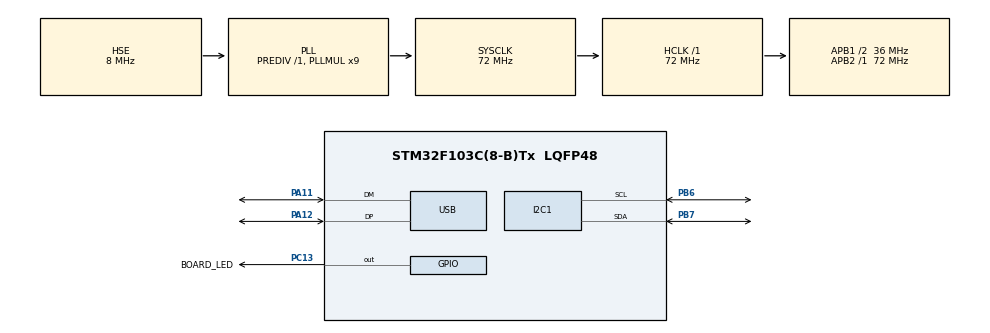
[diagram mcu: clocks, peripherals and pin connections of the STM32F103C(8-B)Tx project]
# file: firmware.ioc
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FREERTOS.Tasks01=imuTask,0,64,imuTaskMain,Default,NULL,Dynamic,NULL,NULL;ledTask,-2,64,ledTaskMain,Default,NULL,Dynamic,NULL,NULL;cdcTask,0,64,cdcTaskMain,Default,NULL,Dynamic,NULL,NULL
FREERTOS.configMINIMAL_STACK_SIZE=64
I2C1.I2C_Mode=I2C_Standard
Mcu.Family=STM32F1
Mcu.Name=STM32F103C(8-B)Tx
Mcu.Package=LQFP48
NVIC.PriorityGroup=NVIC_PRIORITYGROUP_4
NVIC.TIM1_UP_IRQn=true\:0\:0\:false\:false\:true\:false\:false
NVIC.TimeBase=TIM1_UP_IRQn
NVIC.TimeBaseIP=TIM1
NVIC.USB_LP_CAN1_RX0_IRQn=true\:5\:0\:false\:false\:true\:true\:false
PA11.Mode=Device
PA11.Signal=USB_DM
PA12.Mode=Device
PA12.Signal=USB_DP
PA13.Mode=Serial_Wire
PA13.Signal=SYS_JTMS-SWDIO
PA14.Mode=Serial_Wire
PA14.Signal=SYS_JTCK-SWCLK
PB6.Mode=I2C
PB6.Signal=I2C1_SCL
PB7.Mode=I2C
PB7.Signal=I2C1_SDA
PC13-TAMPER-RTC.GPIO_Label=BOARD_LED
PC13-TAMPER-RTC.Signal=GPIO_Output
PD0-OSC_IN.GPIO_Label=XTAL_IN
PD0-OSC_IN.Mode=HSE-External-Oscillator
PD0-OSC_IN.Signal=RCC_OSC_IN
PD1-OSC_OUT.GPIO_Label=XTAL_OUT
PD1-OSC_OUT.Mode=HSE-External-Oscillator
PD1-OSC_OUT.Signal=RCC_OSC_OUT
ProjectManager.HeapSize=0x200
ProjectManager.StackSize=0x400
ProjectManager.TargetToolchain=TrueSTUDIO
RCC.AHBFreq_Value=72000000
RCC.APB1CLKDivider=RCC_HCLK_DIV2
RCC.APB1Freq_Value=36000000
RCC.APB1TimFreq_Value=72000000
RCC.APB2Freq_Value=72000000
RCC.APB2TimFreq_Value=72000000
RCC.HCLKFreq_Value=72000000
RCC.PLLMUL=RCC_PLL_MUL9
RCC.PLLSourceVirtual=RCC_PLLSOURCE_HSE
RCC.RTCClockSelection=RCC_RTCCLKSOURCE_LSE
RCC.SYSCLKFreq_VALUE=72000000
RCC.SYSCLKSource=RCC_SYSCLKSOURCE_PLLCLK
RCC.USBFreq_Value=48000000
RCC.USBPrescaler=RCC_USBCLKSOURCE_PLL_DIV1_5
USB.ep0_mps=DEP0CTL_MPS_64
USB_DEVICE.CLASS_NAME_FS=CDC
USB_DEVICE.VirtualMode=Cdc
USB_DEVICE.VirtualModeFS=Cdc_FS
VP_FREERTOS_VS_ENABLE.Mode=Enabled
VP_SYS_VS_tim1.Mode=TIM1
VP_USB_DEVICE_VS_USB_DEVICE_CDC_FS.Mode=CDC_FS
board=firmware

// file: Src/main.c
/**
  ******************************************************************************
  * @file           : main.c
  * @brief          : Main program body
  ******************************************************************************
  * This notice applies to any and all portions of this file
  * that are not between comment pairs USER CODE BEGIN and
  * USER CODE END. Other portions of this file, whether
  * inserted by the user or by software development tools
  * are owned by their respective copyright owners.
  *
  * Copyright (c) 2018 STMicroelectronics International N.V.
  * All rights reserved.
  *
  * Redistribution and use in source and binary forms, with or without
  * modification, are permitted, provided that the following conditions are met:
  *
  * 1. Redistribution of source code must retain the above copyright notice,
  *    this list of conditions and the following disclaimer.
  * 2. Redistributions in binary form must reproduce the above copyright notice,
  *    this list of conditions and the following disclaimer in the documentation
  *    and/or other materials provided with the distribution.
  * 3. Neither the name of STMicroelectronics nor the names of other
  *    contributors to this software may be used to endorse or promote products
  *    derived from this software without specific written permission.
  * 4. This software, including modifications and/or derivative works of this
  *    software, must execute solely and exclusively on microcontroller or
  *    microprocessor devices manufactured by or for STMicroelectronics.
  * 5. Redistribution and use of this software other than as permitted under
  *    this license is void and will automatically terminate your rights under
  *    this license.
  *
  * THIS SOFTWARE IS PROVIDED BY STMICROELECTRONICS AND CONTRIBUTORS "AS IS"
  * AND ANY EXPRESS, IMPLIED OR STATUTORY WARRANTIES, INCLUDING, BUT NOT
  * LIMITED TO, THE IMPLIED WARRANTIES OF MERCHANTABILITY, FITNESS FOR A
  * PARTICULAR PURPOSE AND NON-INFRINGEMENT OF THIRD PARTY INTELLECTUAL PROPERTY
  * RIGHTS ARE DISCLAIMED TO THE FULLEST EXTENT PERMITTED BY LAW. IN NO EVENT
  * SHALL STMICROELECTRONICS OR CONTRIBUTORS BE LIABLE FOR ANY DIRECT, INDIRECT,
  * INCIDENTAL, SPECIAL, EXEMPLARY, OR CONSEQUENTIAL DAMAGES (INCLUDING, BUT NOT
  * LIMITED TO, PROCUREMENT OF SUBSTITUTE GOODS OR SERVICES; LOSS OF USE, DATA,
  * OR PROFITS; OR BUSINESS INTERRUPTION) HOWEVER CAUSED AND ON ANY THEORY OF
  * LIABILITY, WHETHER IN CONTRACT, STRICT LIABILITY, OR TORT (INCLUDING
  * NEGLIGENCE OR OTHERWISE) ARISING IN ANY WAY OUT OF THE USE OF THIS SOFTWARE,
  * EVEN IF ADVISED OF THE POSSIBILITY OF SUCH DAMAGE.
  *
  ******************************************************************************
  */
#include "main.h"
#include "stm32f1xx_hal.h"
#include "cmsis_os.h"
#include "usb_device.h"

/* USER CODE BEGIN Includes */
#include "firmware.h"
/* USER CODE END Includes */

I2C_HandleTypeDef hi2c1;

osThreadId imuTaskHandle;
osThreadId ledTaskHandle;
osThreadId cdcTaskHandle;

/* USER CODE BEGIN PV */
/* Private variables ---------------------------------------------------------*/

/* USER CODE END PV */

void SystemClock_Config(void);
static void MX_GPIO_Init(void);
static void MX_I2C1_Init(void);
void imuTaskMain(void const * argument);
void ledTaskMain(void const * argument);
void cdcTaskMain(void const * argument);

/* USER CODE BEGIN PFP */
/* Private function prototypes -----------------------------------------------*/
/* USER CODE END PFP */

int main(void)
{

  /* MCU Configuration----------------------------------------------------------*/

  /* Reset of all peripherals, Initializes the Flash interface and the Systick. */
  HAL_Init();

  /* Configure the system clock */
  SystemClock_Config();

  /* Initialize all configured peripherals */
  MX_GPIO_Init();
  MX_I2C1_Init();

  /* Create the thread(s) */
  /* definition and creation of imuTask */
  osThreadDef(imuTask, imuTaskMain, osPriorityNormal, 0, 64);
  imuTaskHandle = osThreadCreate(osThread(imuTask), NULL);

  /* definition and creation of ledTask */
  osThreadDef(ledTask, ledTaskMain, osPriorityLow, 0, 64);
  ledTaskHandle = osThreadCreate(osThread(ledTask), NULL);

  /* definition and creation of cdcTask */
  osThreadDef(cdcTask, cdcTaskMain, osPriorityNormal, 0, 64);
  cdcTaskHandle = osThreadCreate(osThread(cdcTask), NULL);

  /* Start scheduler */
  osKernelStart();

  /* We should never get here as control is now taken by the scheduler */

  /* Infinite loop */
  while (1)
  {

  }

}

void SystemClock_Config(void)
{

  RCC_OscInitTypeDef RCC_OscInitStruct;
  RCC_ClkInitTypeDef RCC_ClkInitStruct;
  RCC_PeriphCLKInitTypeDef PeriphClkInit;

    /**Initializes the CPU, AHB and APB busses clocks
    */
  RCC_OscInitStruct.OscillatorType = RCC_OSCILLATORTYPE_HSE;
  RCC_OscInitStruct.HSEState = RCC_HSE_ON;
  RCC_OscInitStruct.HSEPredivValue = RCC_HSE_PREDIV_DIV1;
  RCC_OscInitStruct.HSIState = RCC_HSI_ON;
  RCC_OscInitStruct.PLL.PLLState = RCC_PLL_ON;
  RCC_OscInitStruct.PLL.PLLSource = RCC_PLLSOURCE_HSE;
  RCC_OscInitStruct.PLL.PLLMUL = RCC_PLL_MUL9;
  if (HAL_RCC_OscConfig(&RCC_OscInitStruct) != HAL_OK)
  {
    _Error_Handler(__FILE__, __LINE__);
  }

    /**Initializes the CPU, AHB and APB busses clocks
    */
  RCC_ClkInitStruct.ClockType = RCC_CLOCKTYPE_HCLK|RCC_CLOCKTYPE_SYSCLK
                              |RCC_CLOCKTYPE_PCLK1|RCC_CLOCKTYPE_PCLK2;
  RCC_ClkInitStruct.SYSCLKSource = RCC_SYSCLKSOURCE_PLLCLK;
  RCC_ClkInitStruct.AHBCLKDivider = RCC_SYSCLK_DIV1;
  RCC_ClkInitStruct.APB1CLKDivider = RCC_HCLK_DIV2;
  RCC_ClkInitStruct.APB2CLKDivider = RCC_HCLK_DIV1;

  if (HAL_RCC_ClockConfig(&RCC_ClkInitStruct, FLASH_LATENCY_2) != HAL_OK)
  {
    _Error_Handler(__FILE__, __LINE__);
  }

  PeriphClkInit.PeriphClockSelection = RCC_PERIPHCLK_USB;
  PeriphClkInit.UsbClockSelection = RCC_USBCLKSOURCE_PLL_DIV1_5;
  if (HAL_RCCEx_PeriphCLKConfig(&PeriphClkInit) != HAL_OK)
  {
    _Error_Handler(__FILE__, __LINE__);
  }

    /**Configure the Systick interrupt time
    */
  HAL_SYSTICK_Config(HAL_RCC_GetHCLKFreq()/1000);

    /**Configure the Systick
    */
  HAL_SYSTICK_CLKSourceConfig(SYSTICK_CLKSOURCE_HCLK);

  /* SysTick_IRQn interrupt configuration */
  HAL_NVIC_SetPriority(SysTick_IRQn, 15, 0);
}

/* I2C1 init function */
static void MX_I2C1_Init(void)
{

  hi2c1.Instance = I2C1;
  hi2c1.Init.ClockSpeed = 100000;
  hi2c1.Init.DutyCycle = I2C_DUTYCYCLE_2;
  hi2c1.Init.OwnAddress1 = 0;
  hi2c1.Init.AddressingMode = I2C_ADDRESSINGMODE_7BIT;
  hi2c1.Init.DualAddressMode = I2C_DUALADDRESS_DISABLE;
  hi2c1.Init.OwnAddress2 = 0;
  hi2c1.Init.GeneralCallMode = I2C_GENERALCALL_DISABLE;
  hi2c1.Init.NoStretchMode = I2C_NOSTRETCH_DISABLE;
  if (HAL_I2C_Init(&hi2c1) != HAL_OK)
  {
    _Error_Handler(__FILE__, __LINE__);
  }

}

/** Configure pins as
        * Analog
        * Input
        * Output
        * EVENT_OUT
        * EXTI
*/
static void MX_GPIO_Init(void)
{

  GPIO_InitTypeDef GPIO_InitStruct;

  /* GPIO Ports Clock Enable */
  __HAL_RCC_GPIOC_CLK_ENABLE();
  __HAL_RCC_GPIOD_CLK_ENABLE();
  __HAL_RCC_GPIOA_CLK_ENABLE();
  __HAL_RCC_GPIOB_CLK_ENABLE();

  /*Configure GPIO pin Output Level */
  HAL_GPIO_WritePin(BOARD_LED_GPIO_Port, BOARD_LED_Pin, GPIO_PIN_RESET);

  /*Configure GPIO pin : BOARD_LED_Pin */
  GPIO_InitStruct.Pin = BOARD_LED_Pin;
  GPIO_InitStruct.Mode = GPIO_MODE_OUTPUT_PP;
  GPIO_InitStruct.Speed = GPIO_SPEED_FREQ_LOW;
  HAL_GPIO_Init(BOARD_LED_GPIO_Port, &GPIO_InitStruct);

}

/* imuTaskMain function */
void imuTaskMain(void const * argument)
{
  /* init code for USB_DEVICE */
  MX_USB_DEVICE_Init();

  /* USER CODE BEGIN 5 */
  /* Infinite loop */
  for(;;)
  {
    // execute main function
    imuMain();

    // os delay time
    osDelay(IMU_TASK_IDLE_TIME_MS);
  }
  /* USER CODE END 5 */
}

/* ledTaskMain function */
void ledTaskMain(void const * argument)
{
  /* USER CODE BEGIN ledTaskMain */
  /* Infinite loop */
  for(;;)
  {
    // execute main function
    ledMain();

    // os delay time
    osDelay(LED_TASK_IDLE_TIME_MS);
  }
  /* USER CODE END ledTaskMain */
}

/* cdcTaskMain function */
void cdcTaskMain(void const * argument)
{
  /* USER CODE BEGIN cdcTaskMain */
  /* Infinite loop */
  for(;;)
  {
    // execute main function
    cdcMain();

    // os delay time
    osDelay(CDC_TASK_IDLE_TIME_MS);
  }
  /* USER CODE END cdcTaskMain */
}

void HAL_TIM_PeriodElapsedCallback(TIM_HandleTypeDef *htim)
{
  if (htim->Instance == TIM1) {
    HAL_IncTick();
  }
}

void _Error_Handler(char *file, int line)
{
  while(1)
  {
  }
}

/************************ (C) COPYRIGHT STMicroelectronics *****END OF FILE****/
